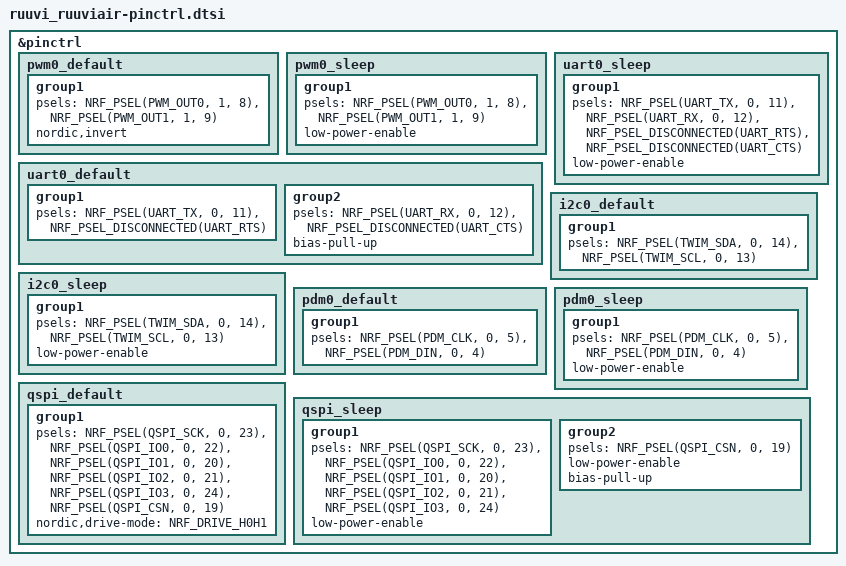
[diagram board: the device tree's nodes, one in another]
/**
 * @copyright Ruuvi Innovations Ltd, license BSD-3-Clause.
 */

&pinctrl {
	pwm0_default: pwm0_default {
		group1 {
			psels = <NRF_PSEL(PWM_OUT0, 1, 8)>, <NRF_PSEL(PWM_OUT1, 1, 9)>;
			nordic,invert;
		};
	};

	pwm0_sleep: pwm0_sleep {
		group1 {
			psels = <NRF_PSEL(PWM_OUT0, 1, 8)>, <NRF_PSEL(PWM_OUT1, 1, 9)>;
			low-power-enable;
		};
	};

	uart0_default: uart0_default {
		group1 {
			psels = <NRF_PSEL(UART_TX, 0, 11)>,
				<NRF_PSEL_DISCONNECTED(UART_RTS)>;
		};
		group2 {
			psels = <NRF_PSEL(UART_RX, 0, 12)>,
				<NRF_PSEL_DISCONNECTED(UART_CTS)>;
			bias-pull-up;
		};
	};

	uart0_sleep: uart0_sleep {
		group1 {
			psels = <NRF_PSEL(UART_TX, 0, 11)>,
				<NRF_PSEL(UART_RX, 0, 12)>,
				<NRF_PSEL_DISCONNECTED(UART_RTS)>,
				<NRF_PSEL_DISCONNECTED(UART_CTS)>;
			low-power-enable;
		};
	};

	i2c0_default: i2c0_default {
		group1 {
			psels = <NRF_PSEL(TWIM_SDA, 0, 14)>,
				<NRF_PSEL(TWIM_SCL, 0, 13)>;
		};
	};

	i2c0_sleep: i2c0_sleep {
		group1 {
			psels = <NRF_PSEL(TWIM_SDA, 0, 14)>,
				<NRF_PSEL(TWIM_SCL, 0, 13)>;
			low-power-enable;
		};
	};

	pdm0_default: pdm0_default {
		group1 {
			psels = <NRF_PSEL(PDM_CLK, 0, 5)>,
				<NRF_PSEL(PDM_DIN, 0, 4)>;
		};
	};

	pdm0_sleep: pdm0_sleep {
		group1 {
			psels = <NRF_PSEL(PDM_CLK, 0, 5)>,
				<NRF_PSEL(PDM_DIN, 0, 4)>;
			low-power-enable;
		};
	};

	qspi_default: qspi_default {
		group1 {
			psels = <NRF_PSEL(QSPI_SCK, 0, 23)>,
				<NRF_PSEL(QSPI_IO0, 0, 22)>,
				<NRF_PSEL(QSPI_IO1, 0, 20)>,
				<NRF_PSEL(QSPI_IO2, 0, 21)>,
				<NRF_PSEL(QSPI_IO3, 0, 24)>,
				<NRF_PSEL(QSPI_CSN, 0, 19)>;
			nordic,drive-mode = <NRF_DRIVE_H0H1>;
		};
	};

	qspi_sleep: qspi_sleep {
		group1 {
			psels = <NRF_PSEL(QSPI_SCK, 0, 23)>,
				<NRF_PSEL(QSPI_IO0, 0, 22)>,
				<NRF_PSEL(QSPI_IO1, 0, 20)>,
				<NRF_PSEL(QSPI_IO2, 0, 21)>,
				<NRF_PSEL(QSPI_IO3, 0, 24)>;
			low-power-enable;
		};
		group2 {
			psels = <NRF_PSEL(QSPI_CSN, 0, 19)>;
			low-power-enable;
			bias-pull-up;
		};
	};
};
